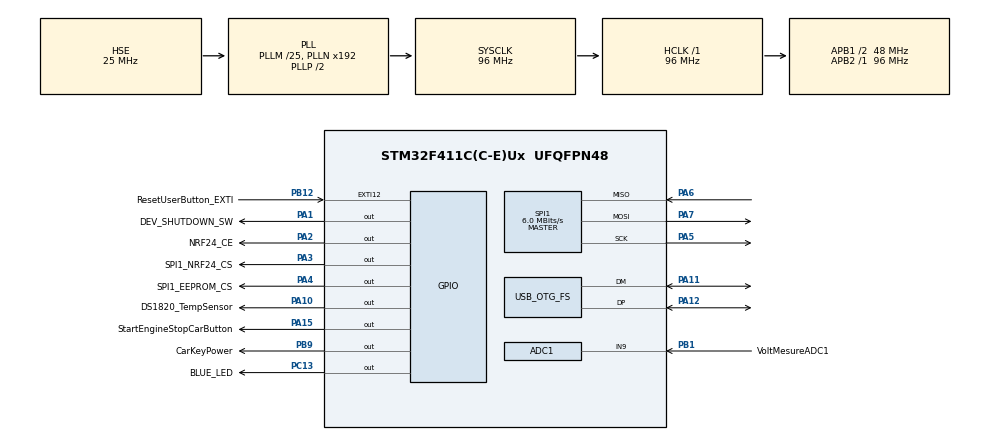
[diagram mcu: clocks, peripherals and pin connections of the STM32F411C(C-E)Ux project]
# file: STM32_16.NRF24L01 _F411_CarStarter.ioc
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ADC1.Channel-0\#ChannelRegularConversion=ADC_CHANNEL_9
ADC1.ContinuousConvMode=ENABLE
ADC1.DMAContinuousRequests=ENABLE
ADC1.NbrOfConversionFlag=1
ADC1.Rank-0\#ChannelRegularConversion=1
ADC1.SamplingTime-0\#ChannelRegularConversion=ADC_SAMPLETIME_480CYCLES
ADC1.master=1
Dma.ADC1.0.Direction=DMA_PERIPH_TO_MEMORY
Dma.ADC1.0.FIFOMode=DMA_FIFOMODE_DISABLE
Dma.ADC1.0.Instance=DMA2_Stream0
Dma.ADC1.0.MemDataAlignment=DMA_MDATAALIGN_HALFWORD
Dma.ADC1.0.MemInc=DMA_MINC_ENABLE
Dma.ADC1.0.Mode=DMA_NORMAL
Dma.ADC1.0.PeriphDataAlignment=DMA_PDATAALIGN_HALFWORD
Dma.ADC1.0.PeriphInc=DMA_PINC_DISABLE
Dma.ADC1.0.Priority=DMA_PRIORITY_LOW
Dma.Request0=ADC1
Mcu.Family=STM32F4
Mcu.Name=STM32F411C(C-E)Ux
Mcu.Package=UFQFPN48
NVIC.DMA2_Stream0_IRQn=true\:3\:0\:true\:false\:true\:false\:true\:true
NVIC.EXTI15_10_IRQn=true\:2\:0\:true\:false\:true\:true\:true\:true
NVIC.OTG_FS_IRQn=true\:4\:0\:true\:false\:true\:true\:true\:true
NVIC.PriorityGroup=NVIC_PRIORITYGROUP_4
NVIC.RTC_WKUP_IRQn=true\:3\:0\:true\:false\:true\:true\:true\:true
NVIC.SPI1_IRQn=true\:4\:0\:true\:false\:true\:true\:true\:true
NVIC.TIM1_UP_TIM10_IRQn=true\:1\:0\:true\:false\:true\:true\:true\:true
PA1.GPIO_Label=DEV_SHUTDOWN_SW
PA1.Signal=GPIO_Output
PA10.GPIO_Label=DS1820_TempSensor
PA10.GPIO_ModeDefaultOutputPP=GPIO_MODE_OUTPUT_OD
PA10.GPIO_PuPd=GPIO_NOPULL
PA10.PinState=GPIO_PIN_SET
PA10.Signal=GPIO_Output
PA11.Mode=Device_Only
PA11.Signal=USB_OTG_FS_DM
PA12.Mode=Device_Only
PA12.Signal=USB_OTG_FS_DP
PA13.Mode=Serial_Wire
PA13.Signal=SYS_JTMS-SWDIO
PA14.Mode=Serial_Wire
PA14.Signal=SYS_JTCK-SWCLK
PA15.GPIO_Label=StartEngineStopCarButton
PA15.Signal=GPIO_Output
PA2.GPIO_Label=NRF24_CE
PA2.Signal=GPIO_Output
PA3.GPIO_Label=SPI1_NRF24_CS
PA3.Signal=GPIO_Output
PA4.GPIO_Label=SPI1_EEPROM_CS
PA4.Signal=GPIO_Output
PA5.Mode=Full_Duplex_Master
PA5.Signal=SPI1_SCK
PA6.Mode=Full_Duplex_Master
PA6.Signal=SPI1_MISO
PA7.Mode=Full_Duplex_Master
PA7.Signal=SPI1_MOSI
PB1.GPIO_Label=VoltMesureADC1
PB1.Signal=ADCx_IN9
PB12.GPIO_Label=ResetUserButton_EXTI
PB12.Signal=GPXTI12
PB9.GPIO_Label=CarKeyPower
PB9.GPIO_ModeDefaultOutputPP=GPIO_MODE_OUTPUT_PP
PB9.GPIO_PuPd=GPIO_PULLDOWN
PB9.Signal=GPIO_Output
PC13-ANTI_TAMP.GPIO_Label=BLUE_LED
PC13-ANTI_TAMP.Signal=GPIO_Output
PC14-OSC32_IN.Mode=LSE-External-Oscillator
PC14-OSC32_IN.Signal=RCC_OSC32_IN
PC15-OSC32_OUT.Mode=LSE-External-Oscillator
PC15-OSC32_OUT.Signal=RCC_OSC32_OUT
PH0\ -\ OSC_IN.Mode=HSE-External-Oscillator
PH0\ -\ OSC_IN.Signal=RCC_OSC_IN
PH1\ -\ OSC_OUT.Mode=HSE-External-Oscillator
PH1\ -\ OSC_OUT.Signal=RCC_OSC_OUT
ProjectManager.HeapSize=0x200
ProjectManager.StackSize=0x400
ProjectManager.TargetToolchain=STM32CubeIDE
RCC.48MHZClocksFreq_Value=48000000
RCC.AHBFreq_Value=96000000
RCC.APB1CLKDivider=RCC_HCLK_DIV2
RCC.APB1Freq_Value=48000000
RCC.APB1TimFreq_Value=96000000
RCC.APB2Freq_Value=96000000
RCC.APB2TimFreq_Value=96000000
RCC.CortexFreq_Value=96000000
RCC.HCLKFreq_Value=96000000
RCC.HSE_VALUE=25000000
RCC.HSI_VALUE=16000000
RCC.PLLM=25
RCC.SYSCLKFreq_VALUE=96000000
RCC.SYSCLKSource=RCC_SYSCLKSOURCE_PLLCLK
RCC.VCOOutputFreq_Value=192000000
RTC.SynchPrediv=249
RTC.WakeUpClock=RTC_WAKEUPCLOCK_CK_SPRE_16BITS
RTC.WakeUpCounter=59
SH.ADCx_IN9.0=ADC1_IN9,IN9
SPI1.BaudRatePrescaler=SPI_BAUDRATEPRESCALER_16
SPI1.CalculateBaudRate=6.0 MBits/s
SPI1.Direction=SPI_DIRECTION_2LINES
SPI1.Mode=SPI_MODE_MASTER
SPI1.VirtualType=VM_MASTER
TIM1.Prescaler=95
USB_DEVICE.CLASS_NAME_FS=CDC
USB_DEVICE.VirtualMode=Cdc
USB_DEVICE.VirtualModeFS=Cdc_FS
USB_OTG_FS.VirtualMode=Device_Only
VP_RTC_VS_RTC_Activate.Mode=RTC_Enabled
VP_RTC_VS_RTC_Calendar.Mode=RTC_Calendar
VP_RTC_VS_RTC_WakeUp_intern.Mode=WakeUp
VP_TIM1_VS_ClockSourceINT.Mode=Internal
VP_USB_DEVICE_VS_USB_DEVICE_CDC_FS.Mode=CDC_FS
board=custom
PA3.PinState=GPIO_PIN_SET
PA4.PinState=GPIO_PIN_SET

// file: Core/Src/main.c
/* USER CODE BEGIN Header */
/**
  ******************************************************************************
  * @file           : main.c
  * @brief          : Main program body
  ******************************************************************************
  * @attention
  *
  * Copyright (c) 2026 STMicroelectronics.
  * All rights reserved.
  *
  * This software is licensed under terms that can be found in the LICENSE file
  * in the root directory of this software component.
  * If no LICENSE file comes with this software, it is provided AS-IS.
  *
  ******************************************************************************
  */
/* USER CODE END Header */
#include "main.h"
#include "adc.h"
#include "dma.h"
#include "rtc.h"
#include "spi.h"
#include "tim.h"
#include "usb_device.h"
#include "gpio.h"

/* USER CODE BEGIN Includes */
#include "CarStarter.h"

/* USER CODE END Includes */

void SystemClock_Config(void);

int main(void)
{

  /* MCU Configuration--------------------------------------------------------*/

  /* Reset of all peripherals, Initializes the Flash interface and the Systick. */
  HAL_Init();

  /* Configure the system clock */
  SystemClock_Config();

  /* Initialize all configured peripherals */
  MX_GPIO_Init();
  MX_DMA_Init();
  MX_USB_DEVICE_Init();
  MX_SPI1_Init();
  MX_ADC1_Init();
  MX_RTC_Init();
  MX_TIM1_Init();
  /* USER CODE BEGIN 2 */
  CarStarter_Init();

  /* USER CODE END 2 */

  /* Infinite loop */
  while (1)
  {

    /* USER CODE BEGIN 3 */
    CarStarter_Process();
  }
  /* USER CODE END 3 */
}

void SystemClock_Config(void)
{
  RCC_OscInitTypeDef RCC_OscInitStruct = {0};
  RCC_ClkInitTypeDef RCC_ClkInitStruct = {0};

  /** Configure the main internal regulator output voltage
  */
  __HAL_RCC_PWR_CLK_ENABLE();
  __HAL_PWR_VOLTAGESCALING_CONFIG(PWR_REGULATOR_VOLTAGE_SCALE1);

  /** Initializes the RCC Oscillators according to the specified parameters
  * in the RCC_OscInitTypeDef structure.
  */
  RCC_OscInitStruct.OscillatorType = RCC_OSCILLATORTYPE_LSI|RCC_OSCILLATORTYPE_HSE;
  RCC_OscInitStruct.HSEState = RCC_HSE_ON;
  RCC_OscInitStruct.LSIState = RCC_LSI_ON;
  RCC_OscInitStruct.PLL.PLLState = RCC_PLL_ON;
  RCC_OscInitStruct.PLL.PLLSource = RCC_PLLSOURCE_HSE;
  RCC_OscInitStruct.PLL.PLLM = 25;
  RCC_OscInitStruct.PLL.PLLN = 192;
  RCC_OscInitStruct.PLL.PLLP = RCC_PLLP_DIV2;
  RCC_OscInitStruct.PLL.PLLQ = 4;
  if (HAL_RCC_OscConfig(&RCC_OscInitStruct) != HAL_OK)
  {
    Error_Handler();
  }

  /** Initializes the CPU, AHB and APB buses clocks
  */
  RCC_ClkInitStruct.ClockType = RCC_CLOCKTYPE_HCLK|RCC_CLOCKTYPE_SYSCLK
                              |RCC_CLOCKTYPE_PCLK1|RCC_CLOCKTYPE_PCLK2;
  RCC_ClkInitStruct.SYSCLKSource = RCC_SYSCLKSOURCE_PLLCLK;
  RCC_ClkInitStruct.AHBCLKDivider = RCC_SYSCLK_DIV1;
  RCC_ClkInitStruct.APB1CLKDivider = RCC_HCLK_DIV2;
  RCC_ClkInitStruct.APB2CLKDivider = RCC_HCLK_DIV1;

  if (HAL_RCC_ClockConfig(&RCC_ClkInitStruct, FLASH_LATENCY_3) != HAL_OK)
  {
    Error_Handler();
  }
}

void Error_Handler(void)
{
  __disable_irq();
  while (1)
  {
  }
}
